# ESP32-C5 register map
Vendor: ESPRESSIF SYSTEMS (SHANGHAI) CO., LTD.; Series: ESP32 C-Series; File version: 1
CPU: RV32IMAC r0p0, little endian, no MPU, no FPU, 0 interrupt priority bits
Address unit: 32 bits
Registers are 32-bit, read-write, reset 0x0 unless marked. A register's access mark holds for its fields unless they carry their own. Offsets are from the block's base; [hi:lo] are bit positions; {n}, {i} and the like mark numbered series.

## HUK — HUK Peripheral
Base 0x600B3000
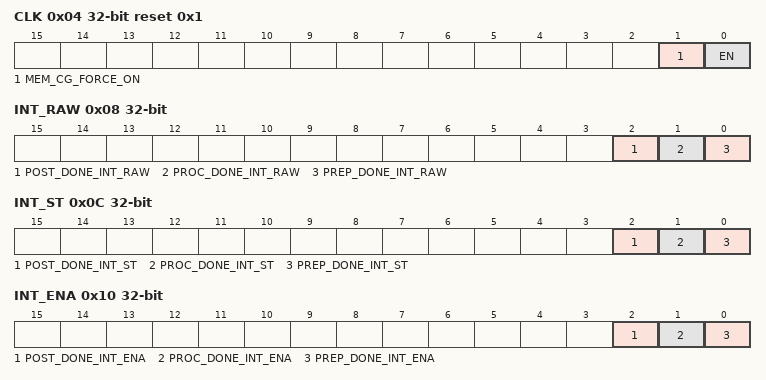
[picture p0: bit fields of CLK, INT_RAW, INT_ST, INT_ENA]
0x04 CLK reset 0x1 — HUK Generator clock gate control register
  [1] MEM_CG_FORCE_ON — Write 1 to force on memory clock gate.
  [0] EN — Write 1 to force on register clock gate.
0x08 INT_RAW ro — HUK Generator interrupt raw register, valid in level.
  [2] POST_DONE_INT_RAW — The raw interrupt status bit for the huk_post_done_int interrupt
  [1] PROC_DONE_INT_RAW — The raw interrupt status bit for the huk_proc_done_int interrupt
  [0] PREP_DONE_INT_RAW — The raw interrupt status bit for the huk_prep_done_int interrupt
0x0C INT_ST ro — HUK Generator interrupt status register.
  [2] POST_DONE_INT_ST — The masked interrupt status bit for the huk_post_done_int interrupt
  [1] PROC_DONE_INT_ST — The masked interrupt status bit for the huk_proc_done_int interrupt
  [0] PREP_DONE_INT_ST — The masked interrupt status bit for the huk_prep_done_int interrupt
0x10 INT_ENA — HUK Generator interrupt enable register.
  [2] POST_DONE_INT_ENA — The interrupt enable bit for the huk_post_done_int interrupt
  [1] PROC_DONE_INT_ENA — The interrupt enable bit for the huk_proc_done_int interrupt
  [0] PREP_DONE_INT_ENA — The interrupt enable bit for the huk_prep_done_int interrupt
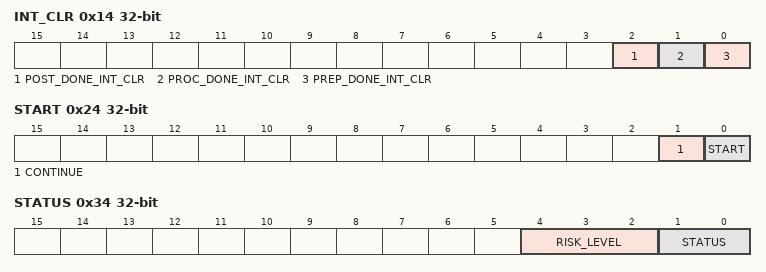
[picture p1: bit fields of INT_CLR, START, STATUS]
0x14 INT_CLR wo — HUK Generator interrupt clear register.
  [2] POST_DONE_INT_CLR — Set this bit to clear the huk_post_done_int interrupt
  [1] PROC_DONE_INT_CLR — Set this bit to clear the huk_proc_done_int interrupt
  [0] PREP_DONE_INT_CLR — Set this bit to clear the huk_prep_done_int interrupt
0x20 CONF — HUK Generator configuration register
  [0] MODE — Set this field to choose the huk process. 1: process huk generate mode. 0: process huk recovery mode.
0x24 START wo — HUK Generator control register
  [1] CONTINUE — Write 1 to start HUK Generator at IDLE state.
  [0] START — Write 1 to continue HUK Generator operation at LOAD/GAIN state.
0x28 STATE ro — HUK Generator state register
  [1:0] STATE — The state of HUK Generator. 0: IDLE. 1: LOAD. 2: GAIN. 3: BUSY.
0x34 STATUS ro — HUK Generator HUK status register
  [4:2] RISK_LEVEL — The risk level of HUK. 0-6: the higher the risk level is, the more error bits there are in the PUF SRAM. 7: Error Level, HUK is invalid.
  [1:0] STATUS — The HUK generation status. 0: HUK is not generated. 1: HUK is generated and valid. 2: HUK is generated but invalid. 3: reserved.
0xFC DATE — Version control register
{0x100+i} INFO_MEM[{i}] (i=0..383) 8-bit access not given — The memory that stores HUK info.

## INTERRUPT_CORE0 — Interrupt Controller (Core 0)
Base 0x60010000
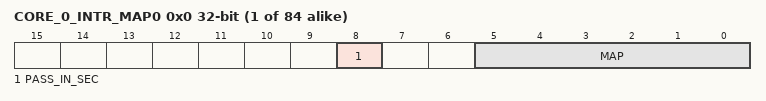
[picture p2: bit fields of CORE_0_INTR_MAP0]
{0x0+4i} CORE_0_INTR_MAP{i} (i=0..83)
  [8] PASS_IN_SEC, [5:0] MAP
{0x150+4i} CORE_0_INTR_STATUS{i} (i=0..2) ro — Represents the status of the interrupt sources. Each bit corresponds to one interrupt source
  [31:0] INT_STATUS_0 — Represents the status of the interrupt sources numbered from .Each bit corresponds to one interrupt source 0:The corresponding interrupt source triggered an interrupt 1:No interrupt triggered
0x7FC INTERRUPT_DATE — Version control register

## INTPRI — INTPRI Peripheral
Base 0x600C5000
{0x90+4i} CPU_INTR_FROM_CPU{i} (i=0..3) — CPU_INTR_FROM_CPU_{i} mapping register
  [0] CPU_INTR — CPU_INTR_FROM_CPU_0 mapping register.
0xA0 DATE — Version control register
0xA4 CLOCK_GATE reset 0x1 — register description
  [0] CLK_EN — Need add description
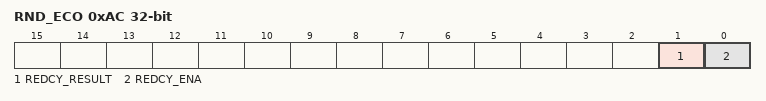
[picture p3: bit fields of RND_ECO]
0xAC RND_ECO access per field — redcy eco register.
  [1] REDCY_RESULT ro — Only reserved for ECO.
  [0] REDCY_ENA rw — Only reserved for ECO.
0xB0 RND_ECO_LOW — redcy eco low register.
  [31:0] REDCY_LOW — Only reserved for ECO.
0x3FC RND_ECO_HIGH reset 0xFFFFFFFF — redcy eco high register.
  [31:0] REDCY_HIGH — Only reserved for ECO.
